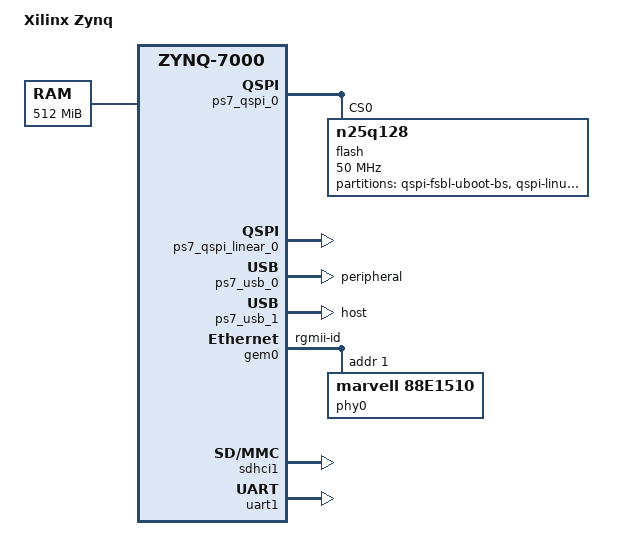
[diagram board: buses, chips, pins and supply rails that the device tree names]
/*
 * Device Tree Generator version: 1.1
 *
 * (C) Copyright 2007-2013 Xilinx, Inc.
 * (C) Copyright 2007-2013 Michal Simek
 * (C) Copyright 2007-2012 PetaLogix Qld Pty Ltd
 *
 * Michal SIMEK <monstr@monstr.eu>
 *
 * CAUTION: This file is automatically generated by libgen.
 * Version: Xilinx EDK 14.7 EDK_P.20131013
 *
 */
/dts-v1/;
/include/ "zynq-7000.dtsi"

/ {
	compatible = "xlnx,zynq-cc108", "xlnx,zynq-7000";
	model = "Xilinx Zynq";

	aliases {
		ethernet0 = &gem0;
		serial0 = &uart1;
		spi0 = &ps7_qspi_0;
	};

	chosen {
		bootargs = "console=ttyPS0,115200 root=/dev/ram rw earlyprintk";
		linux,stdout-path = "/amba/serial@e0001000";
	};

	memory@0 {
		device_type = "memory";
		reg = <0x0 0x20000000>;
	};

	amba {
		ps7_gpio_0: ps7-gpio@e000a000 {
			#gpio-cells = <2>;
			clocks = <&clkc 42>;
			compatible = "xlnx,zynq-gpio-1.0";
			emio-gpio-width = <64>;
			gpio-controller ;
			gpio-mask-high = <0x0>;
			gpio-mask-low = <0x0>;
			interrupt-parent = <&intc>;
			interrupts = <0 20 4>;
			reg = <0xe000a000 0x1000>;
		} ;
		ps7_qspi_0: ps7-qspi@e000d000 {
			clock-names = "ref_clk", "pclk";
			clocks = <&clkc 10>, <&clkc 43>;
			compatible = "xlnx,zynq-qspi-1.0";
			interrupt-parent = <&intc>;
			interrupts = <0 19 4>;
			is-dual = <0>;
			num-cs = <1>;
			reg = <0xe000d000 0x1000>;
			xlnx,fb-clk = <0x0>;
			xlnx,qspi-mode = <0x0>;
			#address-cells = <1>;
			#size-cells = <0>;
			flash@0 { /* 16 MB */
				compatible = "n25q128";
				reg = <0x0>;
				spi-max-frequency = <50000000>;
				spi-tx-bus-width = <1>;
				spi-rx-bus-width = <4>;
				#address-cells = <1>;
				#size-cells = <1>;
				partition@0 {
					label = "qspi-fsbl-uboot-bs";
					reg = <0x0 0x400000>; /* 4MB */
				};
				partition@0x400000 {
					label = "qspi-linux";
					reg = <0x400000 0x400000>; /* 4MB */
				};
				partition@0x800000 {
					label = "qspi-rootfs";
					reg = <0x800000 0x400000>; /* 4MB */
				};
				partition@0xc00000 {
					label = "qspi-devicetree";
					reg = <0xc00000 0x100000>; /* 1MB */
				};
				partition@0xd00000 {
					label = "qspi-scratch";
					reg = <0xd00000 0x200000>; /* 2MB */
				};
				partition@0xf00000 {
					label = "qspi-uboot-env";
					reg = <0xf00000 0x100000>; /* 1MB */
				};
			};
		} ;
		ps7_qspi_linear_0: ps7-qspi-linear@fc000000 {
			clock-names = "ref_clk", "aper_clk";
			clocks = <&clkc 10>, <&clkc 43>;
			compatible = "xlnx,ps7-qspi-linear-1.00.a";
			reg = <0xfc000000 0x1000000>;
		} ;
		ps7_scuwdt_0: ps7-scuwdt@f8f00620 {
			clocks = <&clkc 4>;
			compatible = "xlnx,ps7-scuwdt-1.00.a";
			device_type = "watchdog";
			interrupt-parent = <&intc>;
			interrupts = <1 14 0x301>;
			reg = <0xf8f00620 0xe0>;
		} ;
		ps7_usb_0: ps7-usb@e0002000 {
			clocks = <&clkc 28>;
			compatible = "xlnx,ps7-usb-1.00.a", "xlnx,zynq-usb-1.00.a";
			dr_mode = "peripheral";
			interrupt-parent = <&intc>;
			interrupts = <0 21 4>;
			phy_type = "ulpi";
			reg = <0xe0002000 0x1000>;
			usb-reset = <&ps7_gpio_0 9 0>;
		} ;
		ps7_usb_1: ps7-usb@e0003000 {
			clocks = <&clkc 29>;
			compatible = "xlnx,ps7-usb-1.00.a", "xlnx,zynq-usb-1.00.a";
			dr_mode = "host";
			interrupt-parent = <&intc>;
			interrupts = <0 44 4>;
			phy_type = "ulpi";
			reg = <0xe0003000 0x1000>;
		} ;
		ps7_wdt_0: ps7-wdt@f8005000 {
			clocks = <&clkc 45>;
			compatible = "xlnx,zynq-wdt-r1p2";
			device_type = "watchdog";
			interrupt-parent = <&intc>;
			interrupts = <0 9 1>;
			reg = <0xf8005000 0x1000>;
			reset = <0>;
			timeout-sec = <10>;
		} ;
	};
};

&gem0 {
	status = "okay";
	phy-mode = "rgmii-id";

	phy0: phy@1 {
		compatible = "marvell,88e1510";
		reg = <1>;
	};
};

&sdhci1 {
	status = "okay";
	broken-cd ;
	wp-inverted ;
};

&uart1 {
	status = "okay";
};
